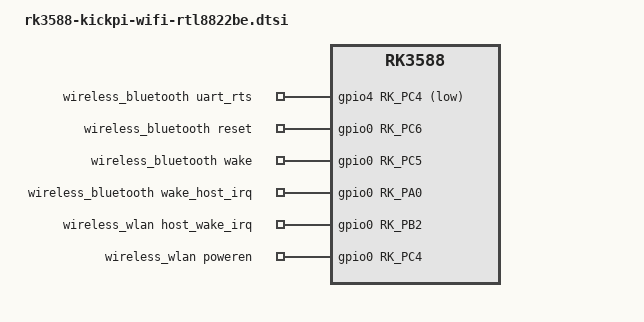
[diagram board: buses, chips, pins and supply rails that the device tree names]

&pinctrl {
	wireless-bluetooth {
		uart9_gpios: uart9-gpios {
			rockchip,pins = <4 RK_PC4 RK_FUNC_GPIO &pcfg_pull_none>;
		};

		bt_reset_gpio: bt-reset-gpio {
			rockchip,pins = <0 RK_PC6 RK_FUNC_GPIO &pcfg_pull_none>;
		};

		bt_wake_gpio: bt-wake-gpio {
			rockchip,pins = <0 RK_PC5 RK_FUNC_GPIO &pcfg_pull_none>;
		};

		bt_irq_gpio: bt-irq-gpio {
			rockchip,pins = <0 RK_PA0 RK_FUNC_GPIO &pcfg_pull_none>;
		};
	};

	wireless-wlan {
		wifi_host_wake_irq: wifi-host-wake-irq {
			rockchip,pins = <0 RK_PB2 RK_FUNC_GPIO &pcfg_pull_down>;
		};

		wifi_poweren_gpio: wifi-poweren-gpio {
			rockchip,pins = <0 RK_PC4 RK_FUNC_GPIO &pcfg_pull_up>;
		};
	};


};

/ {
	wireless_bluetooth: wireless-bluetooth {
		compatible = "bluetooth-platdata";
		clocks = <&hym8563>;
		clock-names = "ext_clock";
		uart_rts_gpios = <&gpio4 RK_PC4 GPIO_ACTIVE_LOW>;
		pinctrl-names = "default", "rts_gpio";
		pinctrl-0 = <&uart9m0_rtsn>, <&bt_reset_gpio>, <&bt_wake_gpio>, <&bt_irq_gpio>;
		pinctrl-1 = <&uart9_gpios>;
		BT,reset_gpio    = <&gpio0 RK_PC6 GPIO_ACTIVE_HIGH>;
		BT,wake_gpio     = <&gpio0 RK_PC5 GPIO_ACTIVE_HIGH>;
		BT,wake_host_irq = <&gpio0 RK_PA0 GPIO_ACTIVE_HIGH>;
		status = "okay";
	};

	wireless_wlan: wireless-wlan {
		compatible = "wlan-platdata";
		wifi_chip_type = "8852be";
		pinctrl-names = "default";
		pinctrl-0 = <&wifi_host_wake_irq>;
		WIFI,host_wake_irq = <&gpio0 RK_PB2 GPIO_ACTIVE_HIGH>;
		WIFI,poweren_gpio = <&gpio0 RK_PC4 GPIO_ACTIVE_HIGH>;
		status = "okay";
	};
    
};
